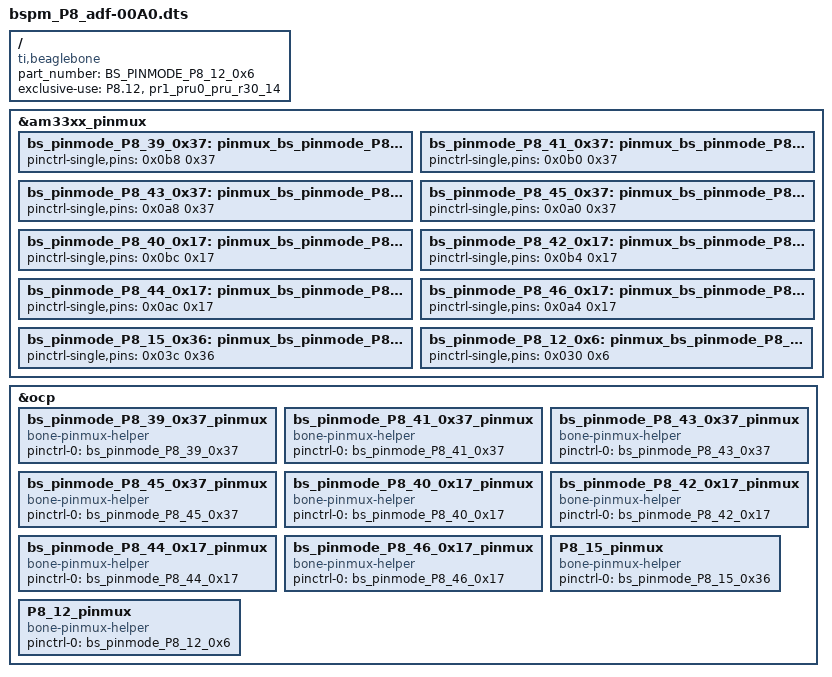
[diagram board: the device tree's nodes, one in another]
/*
 * This is a template-generated file from BoneScript
 */

/dts-v1/;
/plugin/;
/*
 * This is a template-generated file from BoneScript
 */

/dts-v1/;
/plugin/;

/{
    compatible = "ti,beaglebone", "ti,beaglebone-black";
    part_number = "BS_PINMODE_P8_39_0x37";

    exclusive-use =
        "P8.39",
        "gpio2_12";

    fragment@0 {
        target = <&am33xx_pinmux>;
        __overlay__ {
            bs_pinmode_P8_39_0x37: pinmux_bs_pinmode_P8_39_0x37 {
                pinctrl-single,pins = <0x0b8 0x37>;
            };
        };
    };

    fragment@1 {
        target = <&ocp>;
        __overlay__ {
            bs_pinmode_P8_39_0x37_pinmux {
                compatible = "bone-pinmux-helper";
                status = "okay";
                pinctrl-names = "default";
                pinctrl-0 = <&bs_pinmode_P8_39_0x37>;
            };
        };
    };
};

/{
    compatible = "ti,beaglebone", "ti,beaglebone-black";
    part_number = "BS_PINMODE_P8_41_0x37";

    exclusive-use =
        "P8.41",
        "gpio2_10";

    fragment@0 {
        target = <&am33xx_pinmux>;
        __overlay__ {
            bs_pinmode_P8_41_0x37: pinmux_bs_pinmode_P8_41_0x37 {
                pinctrl-single,pins = <0x0b0 0x37>;
            };
        };
    };

    fragment@1 {
        target = <&ocp>;
        __overlay__ {
            bs_pinmode_P8_41_0x37_pinmux {
                compatible = "bone-pinmux-helper";
                status = "okay";
                pinctrl-names = "default";
                pinctrl-0 = <&bs_pinmode_P8_41_0x37>;
            };
        };
    };
};

/{
    compatible = "ti,beaglebone", "ti,beaglebone-black";
    part_number = "BS_PINMODE_P8_43_0x37";

    exclusive-use =
        "P8.43",
        "gpio2_8";

    fragment@0 {
        target = <&am33xx_pinmux>;
        __overlay__ {
            bs_pinmode_P8_43_0x37: pinmux_bs_pinmode_P8_43_0x37 {
                pinctrl-single,pins = <0x0a8 0x37>;
            };
        };
    };

    fragment@1 {
        target = <&ocp>;
        __overlay__ {
            bs_pinmode_P8_43_0x37_pinmux {
                compatible = "bone-pinmux-helper";
                status = "okay";
                pinctrl-names = "default";
                pinctrl-0 = <&bs_pinmode_P8_43_0x37>;
            };
        };
    };
};

/{
    compatible = "ti,beaglebone", "ti,beaglebone-black";
    part_number = "BS_PINMODE_P8_45_0x37";

    exclusive-use =
        "P8.45",
        "gpio2_6";

    fragment@0 {
        target = <&am33xx_pinmux>;
        __overlay__ {
            bs_pinmode_P8_45_0x37: pinmux_bs_pinmode_P8_45_0x37 {
                pinctrl-single,pins = <0x0a0 0x37>;
            };
        };
    };

    fragment@1 {
        target = <&ocp>;
        __overlay__ {
            bs_pinmode_P8_45_0x37_pinmux {
                compatible = "bone-pinmux-helper";
                status = "okay";
                pinctrl-names = "default";
                pinctrl-0 = <&bs_pinmode_P8_45_0x37>;
            };
        };
    };
};

/{
    compatible = "ti,beaglebone", "ti,beaglebone-black";
    part_number = "BS_PINMODE_P8_40_0x17";

    exclusive-use =
        "P8.40",
        "gpio2_13";

    fragment@0 {
        target = <&am33xx_pinmux>;
        __overlay__ {
            bs_pinmode_P8_40_0x17: pinmux_bs_pinmode_P8_40_0x17 {
                pinctrl-single,pins = <0x0bc 0x17>;
            };
        };
    };

    fragment@1 {
        target = <&ocp>;
        __overlay__ {
            bs_pinmode_P8_40_0x17_pinmux {
                compatible = "bone-pinmux-helper";
                status = "okay";
                pinctrl-names = "default";
                pinctrl-0 = <&bs_pinmode_P8_40_0x17>;
            };
        };
    };
};

/{
    compatible = "ti,beaglebone", "ti,beaglebone-black";
    part_number = "BS_PINMODE_P8_42_0x17";

    exclusive-use =
        "P8.42",
        "gpio2_11";

    fragment@0 {
        target = <&am33xx_pinmux>;
        __overlay__ {
            bs_pinmode_P8_42_0x17: pinmux_bs_pinmode_P8_42_0x17 {
                pinctrl-single,pins = <0x0b4 0x17>;
            };
        };
    };

    fragment@1 {
        target = <&ocp>;
        __overlay__ {
            bs_pinmode_P8_42_0x17_pinmux {
                compatible = "bone-pinmux-helper";
                status = "okay";
                pinctrl-names = "default";
                pinctrl-0 = <&bs_pinmode_P8_42_0x17>;
            };
        };
    };
};

/{
    compatible = "ti,beaglebone", "ti,beaglebone-black";
    part_number = "BS_PINMODE_P8_44_0x17";

    exclusive-use =
        "P8.44",
        "gpio2_9";

    fragment@0 {
        target = <&am33xx_pinmux>;
        __overlay__ {
            bs_pinmode_P8_44_0x17: pinmux_bs_pinmode_P8_44_0x17 {
                pinctrl-single,pins = <0x0ac 0x17>;
            };
        };
    };

    fragment@1 {
        target = <&ocp>;
        __overlay__ {
            bs_pinmode_P8_44_0x17_pinmux {
                compatible = "bone-pinmux-helper";
                status = "okay";
                pinctrl-names = "default";
                pinctrl-0 = <&bs_pinmode_P8_44_0x17>;
            };
        };
    };
};

/{
    compatible = "ti,beaglebone", "ti,beaglebone-black";
    part_number = "BS_PINMODE_P8_46_0x17";

    exclusive-use =
        "P8.46",
        "gpio2_7";

    fragment@0 {
        target = <&am33xx_pinmux>;
        __overlay__ {
            bs_pinmode_P8_46_0x17: pinmux_bs_pinmode_P8_46_0x17 {
                pinctrl-single,pins = <0x0a4 0x17>;
            };
        };
    };

    fragment@1 {
        target = <&ocp>;
        __overlay__ {
            bs_pinmode_P8_46_0x17_pinmux {
                compatible = "bone-pinmux-helper";
                status = "okay";
                pinctrl-names = "default";
                pinctrl-0 = <&bs_pinmode_P8_46_0x17>;
            };
        };
    };
};

/{
    compatible = "ti,beaglebone", "ti,beaglebone-black";
    part_number = "BS_PINMODE_P8_15_0x36";

    exclusive-use =
        "P8.15",
        "pr1_pru0_pru_r31_15";

    fragment@0 {
        target = <&am33xx_pinmux>;
        __overlay__ {
            bs_pinmode_P8_15_0x36: pinmux_bs_pinmode_P8_15_0x36 {
                pinctrl-single,pins = <0x03c 0x36>;
            };
        };
    };

    fragment@1 {
        target = <&ocp>;
        __overlay__ {
            P8_15_pinmux {
                compatible = "bone-pinmux-helper";
                status = "okay";
                pinctrl-names = "default";
                pinctrl-0 = <&bs_pinmode_P8_15_0x36>;
            };
        };
    };
};

/{
    compatible = "ti,beaglebone", "ti,beaglebone-black";
    part_number = "BS_PINMODE_P8_12_0x6";

    exclusive-use =
        "P8.12",
        "pr1_pru0_pru_r30_14";

    fragment@0 {
        target = <&am33xx_pinmux>;
        __overlay__ {
            bs_pinmode_P8_12_0x6: pinmux_bs_pinmode_P8_12_0x6 {
                pinctrl-single,pins = <0x030 0x6>;
            };
        };
    };

    fragment@1 {
        target = <&ocp>;
        __overlay__ {
            P8_12_pinmux {
                compatible = "bone-pinmux-helper";
                status = "okay";
                pinctrl-names = "default";
                pinctrl-0 = <&bs_pinmode_P8_12_0x6>;
            };
        };
    };
};

